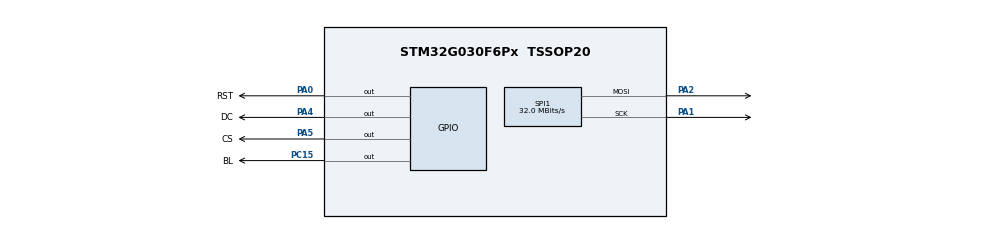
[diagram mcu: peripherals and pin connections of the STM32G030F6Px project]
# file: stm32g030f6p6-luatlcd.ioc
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Mcu.Family=STM32G0
Mcu.Name=STM32G030F6Px
Mcu.Package=TSSOP20
PA0.GPIO_Label=RST
PA0.Signal=GPIO_Output
PA1.GPIO_Speed=GPIO_SPEED_FREQ_VERY_HIGH
PA1.Mode=TX_Only_Simplex_Unidirect_Master
PA1.Signal=SPI1_SCK
PA14-BOOT0__PA15.StandardMode=true
PA2.GPIO_Speed=GPIO_SPEED_FREQ_VERY_HIGH
PA2.Mode=TX_Only_Simplex_Unidirect_Master
PA2.Signal=SPI1_MOSI
PA4.GPIO_Label=DC
PA4.GPIO_Speed=GPIO_SPEED_FREQ_VERY_HIGH
PA4.Signal=GPIO_Output
PA5.GPIO_Label=CS
PA5.Signal=GPIO_Output
PB0__PB1__PB2__PA8.StandardMode=true
PB3__PB4__PB5__PB6.StandardMode=true
PB7__PB8.StandardMode=true
PC14-OSC32_IN\ (PC14)__PB9.StandardMode=true
PC15-OSC32_OUT\ (PC15).GPIO_Label=BL
PC15-OSC32_OUT\ (PC15).Signal=GPIO_Output
ProjectManager.HeapSize=0x1000
ProjectManager.StackSize=0x800
ProjectManager.TargetToolchain=MDK-ARM V5.32
RCC.ADCFreq_Value=64000000
RCC.AHBFreq_Value=64000000
RCC.CortexFreq_Value=64000000
RCC.EXTERNAL_CLOCK_VALUE=12288000
RCC.HCLKFreq_Value=64000000
RCC.HSE_VALUE=8000000
RCC.HSI_VALUE=16000000
RCC.LSE_VALUE=32768
RCC.SYSCLKFreq_VALUE=64000000
RCC.SYSCLKSource=RCC_SYSCLKSOURCE_PLLCLK
RCC.VCOOutputFreq_Value=128000000
SPI1.CLKPhase=SPI_PHASE_1EDGE
SPI1.CalculateBaudRate=32.0 MBits/s
SPI1.Direction=SPI_DIRECTION_2LINES
SPI1.Mode=SPI_MODE_MASTER
SPI1.NSSPMode=SPI_NSS_PULSE_DISABLE
SPI1.VirtualType=VM_MASTER
board=custom

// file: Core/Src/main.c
/* USER CODE BEGIN Header */
/**
  ******************************************************************************
  * @file           : main.c
  * @brief          : Main program body
  ******************************************************************************
  * @attention
  *
  * Copyright (c) 2022 STMicroelectronics.
  * All rights reserved.
  *
  * This software is licensed under terms that can be found in the LICENSE file
  * in the root directory of this software component.
  * If no LICENSE file comes with this software, it is provided AS-IS.
  *
  ******************************************************************************
  */
/* USER CODE END Header */
#include "main.h"
#include "spi.h"
#include "gpio.h"

/* USER CODE BEGIN Includes */
#include "lcd.h"
// #include "arm_2d.h"
// #include "arm_2d_helper.h"
/* USER CODE END Includes */

void SystemClock_Config(void);
/* USER CODE BEGIN PFP */

//  static
//  IMPL_PFB_ON_LOW_LV_RENDERING(__pfb_render_handler)
//  {
//      const arm_2d_tile_t *ptTile = &(ptPFB->tTile);

//      ARM_2D_UNUSED(pTarget);
//      ARM_2D_UNUSED(bIsNewFrame);

//      Disp0_DrawBitmap(ptTile->tRegion.tLocation.iX,
//                      ptTile->tRegion.tLocation.iY,
//                      ptTile->tRegion.tSize.iWidth,
//                      ptTile->tRegion.tSize.iHeight,
//                      ptTile->pchBuffer);

//      arm_2d_helper_pfb_report_rendering_complete(&s_tPFBHelper,
//                                                  (arm_2d_pfb_t *)ptPFB);
//  }

//  static
//  IMPL_PFB_ON_DRAW(__pfb_draw_handler)
//  {
//      ARM_2D_UNUSED(pTarget);
//      arm_2d_region_t tBox = {
//          .tLocation = {30,30},
//          .tSize = {40, 40},
//      };
//      //! 背景填充白色
//      arm_2d_rgb16_fill_colour(ptTile, NULL, WHITE);
//      return arm_fsm_rt_cpl;
//  }

/* USER CODE END PFP */

int main(void)
{

  /* MCU Configuration--------------------------------------------------------*/

  /* Reset of all peripherals, Initializes the Flash interface and the Systick. */
  LL_APB2_GRP1_EnableClock(LL_APB2_GRP1_PERIPH_SYSCFG);
  LL_APB1_GRP1_EnableClock(LL_APB1_GRP1_PERIPH_PWR);

  /* SysTick_IRQn interrupt configuration */
  NVIC_SetPriority(SysTick_IRQn, 3);

  /* Configure the system clock */
  SystemClock_Config();

  /* Initialize all configured peripherals */
  MX_GPIO_Init();
  MX_SPI1_Init();
  /* USER CODE BEGIN 2 */
  LCD_Init();
   //  arm_2d_init();
   //  ARM_2D_HELPER_PFB_INIT(
   //          &s_tPFBHelper,          //!< FPB Helper object
   //          128,                 //!< screen width
   //          160,                 //!< screen height
   //          uint16_t,   //!< colour date type
   //          128,                 //!< PFB block width
   //          1,                 //!< PFB block height
   //          1   ,      //!< number of PFB in the PFB pool
   //          {
   //              .evtOnLowLevelRendering = {
   //                  //! callback for low level rendering
   //                  .fnHandler = &__pfb_render_handler,
   //              },
   //              .evtOnDrawing = {
   //                  //! callback for drawing GUI
   //                  .fnHandler = &__pfb_draw_handler,
   //              },
   //          },
   //          //.FrameBuffer.bSwapRGB16 = true,
   //      );
  LCD_Fill(0,0,LCD_W, LCD_H, 0xffff);
  /* USER CODE END 2 */

  /* Infinite loop */
  /* USER CODE BEGIN WHILE */
  while (1)
  {
    // arm_2d_helper_pfb_task(&s_tPFBHelper, NULL);
    /* USER CODE END WHILE */

  }
}

void SystemClock_Config(void)
{
  LL_FLASH_SetLatency(LL_FLASH_LATENCY_2);
  while(LL_FLASH_GetLatency() != LL_FLASH_LATENCY_2)
  {
  }

  /* HSI configuration and activation */
  LL_RCC_HSI_Enable();
  while(LL_RCC_HSI_IsReady() != 1)
  {
  }

  /* Main PLL configuration and activation */
  LL_RCC_PLL_ConfigDomain_SYS(LL_RCC_PLLSOURCE_HSI, LL_RCC_PLLM_DIV_1, 8, LL_RCC_PLLR_DIV_2);
  LL_RCC_PLL_Enable();
  LL_RCC_PLL_EnableDomain_SYS();
  while(LL_RCC_PLL_IsReady() != 1)
  {
  }

  /* Set AHB prescaler*/
  LL_RCC_SetAHBPrescaler(LL_RCC_SYSCLK_DIV_1);

  /* Sysclk activation on the main PLL */
  LL_RCC_SetSysClkSource(LL_RCC_SYS_CLKSOURCE_PLL);
  while(LL_RCC_GetSysClkSource() != LL_RCC_SYS_CLKSOURCE_STATUS_PLL)
  {
  }

  /* Set APB1 prescaler*/
  LL_RCC_SetAPB1Prescaler(LL_RCC_APB1_DIV_1);

  LL_Init1msTick(64000000);

  /* Update CMSIS variable (which can be updated also through SystemCoreClockUpdate function) */
  LL_SetSystemCoreClock(64000000);
}

void Error_Handler(void)
{
  __disable_irq();
  while (1)
  {
  }
}
